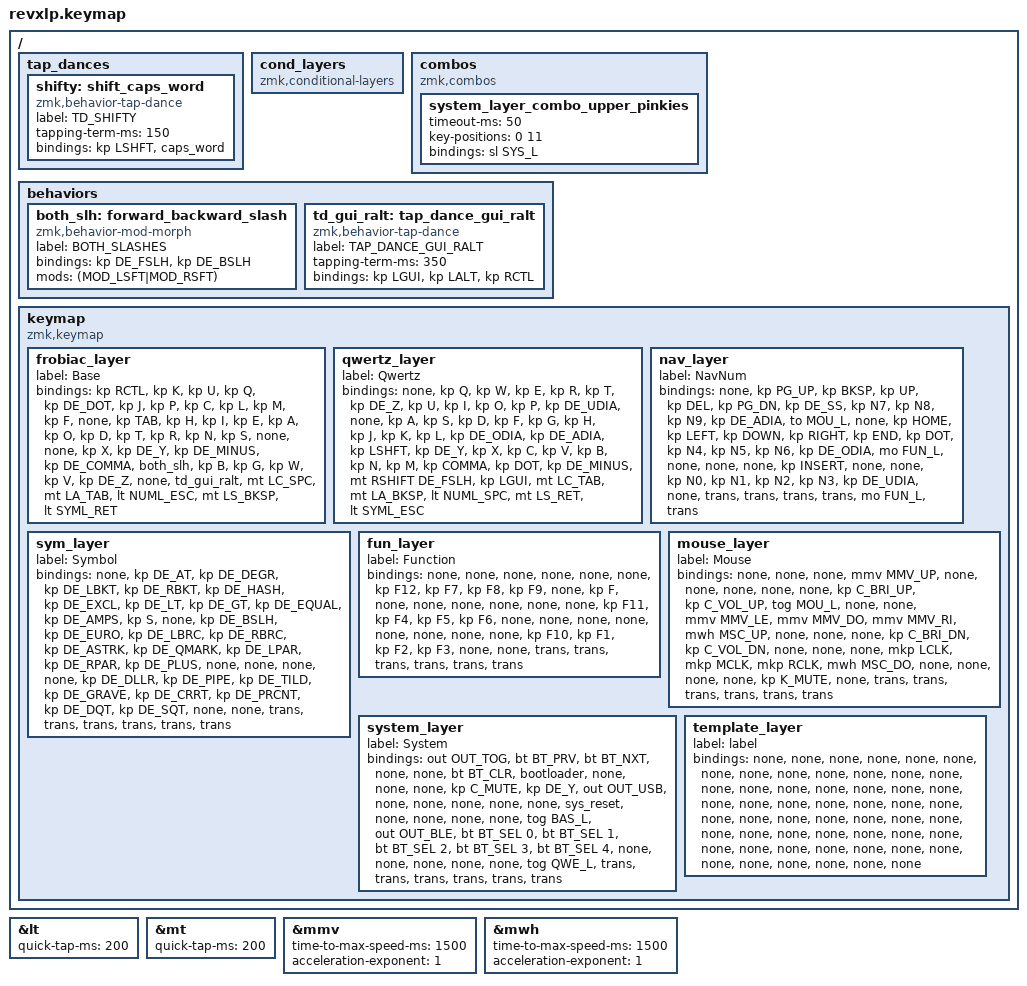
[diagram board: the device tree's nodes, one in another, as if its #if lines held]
/*
 * Copyright (c) 2020 The ZMK Contributors
 *
 * SPDX-License-Identifier: MIT
 */

// [ ] @TODO: MouseLayer possible on ZMK? Separate branch
// [ ] @TODO: Dynamic Macros
// [ ] @TODO: XorShift
// [x] @TODO: Shifted Umlauts must be separately on layer, or order of layer activation will matter
// [x] mod-morph: Different mods on shifted character possible? E.g. '.;' on US, or '/\' on DE?

/*
# Notes on the revxlp hardware

## Build
- Use top-plate during socket mount! Will not snap in everywhere otherwise.
- Mount socket on top side last: Makes assembly of sockets much easier with flat surface
- Pogo pins for reset and bat+ connection to the XIAO BLE prevent using the space below the controller for a battery
  Slim wires fit together with battery. Could use longer sockets to have detachable battery and controller without
  additional space needed.
- JST does not seem to allow battery unter controller, either, or battery protudes under USB.
- Magnetic USB adaptor with round connector prevents battery from passing/being mounted underneath.
- Use center space of board for battery and connectors?

## Hardware
- Outer thumbs create vibrations. Maybe use case-mounted instead of PCB sandwich with more bumpons in between?
  -> Solution: Don't put bumpons further out then last screws, bottom plate was warped and thus lifted the center up from desk.

## Software ZMK
- Conditional Tri-Layer breaks permanent layer toggle with &to / &tog !


## Personal layout
- Default thumb position is in the middle with their alignment here. Must switch Tab and Space for more comfort,
  but not modifiers/layers.
- Inner left thumb as i3 modifier with Alt: any advantages of using Hyper/Meh?
- TapDance
- XIAO leds as indicator: @see blinky example, and boards/arm/xiao_ble/xiao_ble_common.dtsi
  [src](https://docs.zephyrproject.org/latest/boards/arm/xiao_ble/doc/index.html)

*/

#include <behaviors.dtsi>
#include <dt-bindings/zmk/keys.h>
#include <dt-bindings/zmk/bt.h>
#include <dt-bindings/zmk/backlight.h>
#include <dt-bindings/zmk/mouse.h>
#include <dt-bindings/zmk/outputs.h>

// @see https://github.com/bzgec/zmk-config/ for inspiration, and related issue
#include "keys_de.h"

#define BAS_L 0
#define QWE_L 1
#define NUM_L 2
#define SYM_L 3
#define FUN_L 4
#define MOU_L 5
#define SYS_L 6

#include "combos.dtsi" // This include **has** to be made **after** the layers' define, else it won't compile.

// Can use shorter defines to fit into current 12 char alignment.
#define LC_SPC   LCTRL  SPACE
#define LA_TAB   LALT   TAB
#define NUML_ESC NUM_L  ESC
#define LS_BKSP  LSHIFT BKSP
#define SYML_RET SYM_L  RET

// Qwertz (RAS)
#define LC_TAB   LCTRL  TAB
#define LA_BKSP  LALT   BKSP
#define NUML_SPC NUM_L  SPACE
#define LS_RET   LSHIFT RET
#define SYML_ESC SYM_L  ESC

// Allow tap-repeats
&lt {
        quick-tap-ms = <200>;
};
&mt {
        quick-tap-ms = <200>;
};

#define MMV_UP MOVE_VERT(-2000)
#define MMV_DO MOVE_VERT(2000)
#define MMV_LE MOVE_HOR(-2000)
#define MMV_RI MOVE_HOR(2000)
#define MSC_UP SCROLL_VERT(24)
#define MSC_DO SCROLL_VERT(-24)
#define MSC_LE SCROLL_HOR(-24)
#define MSC_RI SCROLL_HOR(24)


&mmv {
    time-to-max-speed-ms = <1500>;
    acceleration-exponent=<1>;
};

&mwh {
    time-to-max-speed-ms = <1500>;
    acceleration-exponent=<1>;
};


/ {
    tap_dances {
    	shifty: shift_caps_word {
		compatible = "zmk,behavior-tap-dance";
		label = "TD_SHIFTY";
		#binding-cells = <0>;
		tapping-term-ms = <150>;
		bindings = <&kp LSHFT>, <&caps_word>;
	    };
    };

    cond_layers {
        compatible = "zmk,conditional-layers";
        /*
        tri {
            // This disables &tog / &to for MOU_L !!!
            if-layers = <NUM_L SYM_L>;
            then-layer = <MOU_L>;
        };
        */
    };

    combos {
        compatible = "zmk,combos";

        system_layer_combo_upper_pinkies {
            timeout-ms = <50>;
                key-positions = <0 11>;
                bindings = <&sl SYS_L>;
        };
    };

    behaviors {
        // To allow non-shifted versions but keeping shift instead of extra layer.
        // Useful also for US-layout version of '.:', ',;' keys
        both_slh: forward_backward_slash {
            compatible = "zmk,behavior-mod-morph";
            label = "BOTH_SLASHES";
            #binding-cells = <0>;
            bindings = <&kp DE_FSLH>, <&kp DE_BSLH>;
            mods = <(MOD_LSFT|MOD_RSFT)>;
        };

        // To be able to use Alt-Tab when both are on the same key due to Tab swap with Space.
        // @TOOD: RAlt-Tab not the same as LAlt-Tab on windows, and double tapping not very easy on left thumb with 200ms.
        td_gui_ralt: tap_dance_gui_ralt {
            compatible = "zmk,behavior-tap-dance";
            label = "TAP_DANCE_GUI_RALT";
            #binding-cells = <0>;
            tapping-term-ms = <350>;
            bindings = <&kp LGUI>, <&kp LALT>, <&kp RCTL>;
        };
    };


    keymap {
        // clang-format off
        compatible = "zmk,keymap";
               // vi{ :EasyAlign * & r0
               // &len_______12 &len_______12 &len_______12 &len_______12 &len_______12 &len_______12 &len_______12 &len_______12 &len_______12 &len_______12 &len_______12 &len_______12

        frobiac_layer { /*
  ╭────────────────────────╮       ╭───────────────────────╮
  │ RCT  K   U   Q   .   J │       │ P   C   L   M   F     │
  │ TAB  H   I   E   A   O │       │ H   J   K   L   ;     │
  │      X   Y   -   ,   / ╰──╮ ╭──╯ B   G   W   V   Z     │
  ╰───────────────╮GUI CTS ATA│ │NES SHB SYR ╭─────────────╯
                  ╰───────────╯ ╰────────────╯            */
            label = "Base";
            bindings = <
                  &kp RCTL      &kp K         &kp U         &kp Q         &kp DE_DOT    &kp J         &kp P         &kp C         &kp L         &kp M         &kp F         &none
                  &kp TAB       &kp H         &kp I         &kp E         &kp A         &kp O         &kp D         &kp T         &kp R         &kp N         &kp S         &none
                  &none         &kp X         &kp DE_Y      &kp DE_MINUS  &kp DE_COMMA  &both_slh     &kp B         &kp G         &kp W         &kp V         &kp DE_Z      &none
               /* &             &             &*/           &td_gui_ralt  &mt LC_SPC    &mt LA_TAB    &lt NUML_ESC  &mt LS_BKSP   &lt SYML_RET
                >;
        };

        qwertz_layer { /* Use lower-right pinky in system layer to activate qwertz layer over frobiac default
  ╭────────────────────────╮       ╭───────────────────────╮
  │      Q   W   E   R   T │       │ Z   U   I   O   P  Ü  │
  │      A   S   D   F   G │       │ H   J   K   L   Ö  Ä  │
  │ LSH  Y   X   C   V   B ╰──╮ ╭──╯ N   M   ,   .   - RSH/│
  ╰───────────────╮GUI CTA ABS│ │NSP SRE SYE ╭─────────────╯
                  ╰───────────╯ ╰────────────╯            */
            label = "Qwertz";
            bindings = <
                  &none         &kp Q         &kp W         &kp E         &kp R         &kp T         &kp DE_Z      &kp U         &kp I         &kp O         &kp P         &kp DE_UDIA
                  &none         &kp A         &kp S         &kp D         &kp F         &kp G         &kp H         &kp J         &kp K         &kp L         &kp DE_ODIA   &kp DE_ADIA
                  &kp LSHFT     &kp DE_Y      &kp X         &kp C         &kp V         &kp B         &kp N         &kp M         &kp COMMA     &kp DOT       &kp DE_MINUS  &mt RSHIFT DE_FSLH
               /* &             &             &*/           &kp LGUI      &mt LC_TAB    &mt LA_BKSP   &lt NUML_SPC  &mt LS_RET    &lt SYML_ESC
            >;
        };

        nav_layer { /*
  ╭────────────────────────╮       ╭───────────────────────╮
  │    PgU BkS Up  Del PgD │       │ ß   7   8   9   ä     │
  │    Hom Lef Dow Rig End │       │ .   4   5   6   ö     │
  │            Ins         ╰──╮ ╭──╯ 0   1   2   3   ü     │
  ╰───────────────╮           │ │            ╭─────────────╯
                  ╰───────────╯ ╰────────────╯            */
            label = "NavNum";
            bindings = <
                  &none         &kp PG_UP     &kp BKSP      &kp UP        &kp DEL       &kp PG_DN     &kp DE_SS     &kp N7        &kp N8        &kp N9        &kp DE_ADIA   &to MOU_L
                  &none         &kp HOME      &kp LEFT      &kp DOWN      &kp RIGHT     &kp END       &kp DOT       &kp N4        &kp N5        &kp N6        &kp DE_ODIA   &mo FUN_L
                  &none         &none         &none         &kp INSERT    &none         &none         &kp N0        &kp N1        &kp N2        &kp N3        &kp DE_UDIA   &none
                  // Accessing FUN_L via LSHIFT from here means that
                  // - for shifted variants in this layer (like the Umlauts, but also directions!) Shift must be pressed prior to NAV_L !
                  // - anything shifted in FUN_L is not available!
                  // Alternatives:
                  // - put shifted umlauts also on FUN_L at same spot
                  // - try L1+L2 vs L2+L1 order for 2 layers
                  // - use a different layer accessor: like center most thumbs but will have similar issues with Alt-Direction then.
                  &trans        &trans        &trans        &trans        &mo FUN_L     &trans
                >;
        };

        sym_layer { /*
  ╭────────────────────────╮       ╭───────────────────────╮
  │      @   °   [   ]   # │       │ !   <   >   =   Amp   │
  │      \   €   {   }   * │       │ ?   (   )   +         │
  │          $   |   ~   ` ╰──╮ ╭──╯ ^   %   "   '         │
  ╰───────────────╮           │ │            ╭─────────────╯
                  ╰───────────╯ ╰────────────╯            */
            label = "Symbol";
            bindings = <
                  &none         &kp DE_AT     &kp DE_DEGR   &kp DE_LBKT   &kp DE_RBKT   &kp DE_HASH   &kp DE_EXCL   &kp DE_LT     &kp DE_GT     &kp DE_EQUAL  &kp DE_AMPS   &kp S
                  &none         &kp DE_BSLH   &kp DE_EURO   &kp DE_LBRC   &kp DE_RBRC   &kp DE_ASTRK  &kp DE_QMARK  &kp DE_LPAR   &kp DE_RPAR   &kp DE_PLUS   &none         &none
                  &none         &none         &kp DE_DLLR   &kp DE_PIPE   &kp DE_TILD   &kp DE_GRAVE  &kp DE_CRRT   &kp DE_PRCNT  &kp DE_DQT    &kp DE_SQT    &none         &none
                  &trans        &trans        &trans        &trans        &trans        &trans
                >;
        };

        fun_layer { /*
  ╭────────────────────────╮       ╭───────────────────────╮
  │                        │       │F12 F7  F8  F9         │
  │                        │       │F11 F4  F5  F6         │
  │                        │       │F10 F1  F2  F3         │
  │                        ╰──╮ ╭──╯                       │
  ╰───────────────╮           │ │            ╭─────────────╯
                  ╰───────────╯ ╰────────────╯            */
            label = "Function";
            bindings = <
                  &none         &none         &none         &none         &none         &none         &kp F12       &kp F7        &kp F8        &kp F9        &none         &kp F
                  &none         &none         &none         &none         &none         &none         &kp F11       &kp F4        &kp F5        &kp F6        &none         &none
                  &none         &none         &none         &none         &none         &none         &kp F10       &kp F1        &kp F2        &kp F3        &none         &none
                  &trans        &trans        &trans        &trans        &trans        &trans
                >;
        };

        mouse_layer { /*
  ╭────────────────────────╮       ╭───────────────────────╮
  │             MUp        │       │ BL        BUp VUp MOU │
  │         MLe MDn MRi WUp│       │ RES       BDn VDn     │
  │         LMB MMB RMB WDn╰──╮ ╭──╯               Mut     │
  ╰───────────────╮           │ │            ╭─────────────╯
                  ╰───────────╯ ╰────────────╯            */
            label = "Mouse";
            bindings = <
                  &none         &none         &none         &mmv MMV_UP   &none         &none         &none         &none         &none         &kp C_BRI_UP  &kp C_VOL_UP  &tog MOU_L
                  &none         &none         &mmv MMV_LE   &mmv MMV_DO   &mmv MMV_RI   &mwh MSC_UP   &none         &none         &none         &kp C_BRI_DN  &kp C_VOL_DN  &none
                  &none         &none         &mkp LCLK     &mkp MCLK     &mkp RCLK     &mwh MSC_DO   &none         &none         &none         &none         &kp K_MUTE    &none
                  &trans        &trans        &trans        &trans        &trans        &trans
                >;
        };

        // Accessed via sticky layer: Repeats are inconvenient, but should not be needed here.
        system_layer { /*
  ╭────────────────────────╮       ╭───────────────────────╮
  │ OUT BT+ BT-        BTX │       │ BOOT          MUT     │
  │ USB                    │       │ RST                   │
  │ BT  BT0 BT1 BT2 BT3 BT4╰──╮ ╭──╯                   QWER│
  ╰───────────────╮           │ │            ╭─────────────╯
                  ╰───────────╯ ╰────────────╯            */
            label = "System";
            bindings = <
                  &out OUT_TOG  &bt BT_PRV    &bt BT_NXT    &none         &none         &bt BT_CLR    &bootloader   &none         &none         &none         &kp C_MUTE    &kp DE_Y
                  &out OUT_USB  &none         &none         &none         &none         &none         &sys_reset    &none         &none         &none         &none         &tog BAS_L
                  &out OUT_BLE  &bt BT_SEL 0  &bt BT_SEL 1  &bt BT_SEL 2  &bt BT_SEL 3  &bt BT_SEL 4  &none         &none         &none         &none         &none         &tog QWE_L
                  &trans        &trans        &trans        &trans        &trans        &trans
                >;
        };

#ifdef ONLY_TEMPLATE
        template_layer {
            label = "label";
            bindings = <
                  &none         &none         &none         &none         &none         &none         &none         &none         &none         &none         &none         &none
                  &none         &none         &none         &none         &none         &none         &none         &none         &none         &none         &none         &none
                  &none         &none         &none         &none         &none         &none         &none         &none         &none         &none         &none         &none
                  &none         &none         &none         &none         &none         &none         &none         &none         &none         &none         &none         &none
               /* &             &             &*/           &none         &none         &none         &none         &none         &none
               // To use with EasyAlign plugin
               // &len_______12 &len_______12 &len_______12 &len_______12 &len_______12 &len_______12 &len_______12 &len_______12 &len_______12 &len_______12 &len_______12 &len_______12
                >;
        };
#endif
    };
};


// vi: ft=dts
